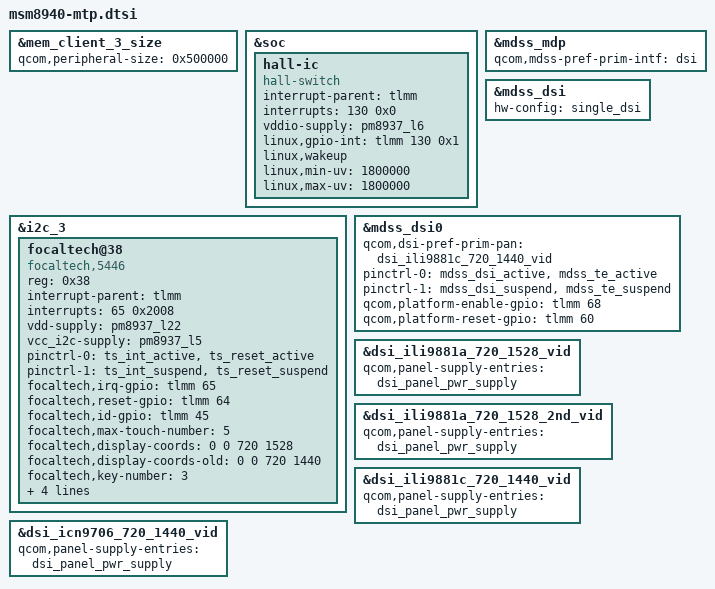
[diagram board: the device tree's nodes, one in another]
/*
 * Copyright (c) 2016, The Linux Foundation. All rights reserved.
 *
 * This program is free software; you can redistribute it and/or modify
 * it under the terms of the GNU General Public License version 2 and
 * only version 2 as published by the Free Software Foundation.
 *
 * This program is distributed in the hope that it will be useful,
 * but WITHOUT ANY WARRANTY; without even the implied warranty of
 * MERCHANTABILITY or FITNESS FOR A PARTICULAR PURPOSE.  See the
 * GNU General Public License for more details.
 */

#include "msm8937-mtp.dtsi"
#include "msm8940-pinctrl.dtsi"

&mem_client_3_size {
	qcom,peripheral-size = <0x500000>;
};

&soc {
	hall-ic{
		compatible = "hall-switch";
		//pinctrl-names = "default";
		//pinctrl-0 = <&hall_sensor_int_default>;
		interrupt-parent = <&tlmm>;
		interrupts = <130 0x0>;
		vddio-supply = <&pm8937_l6>;
		linux,gpio-int = <&tlmm 130 0x1>;
		linux,wakeup;
		linux,min-uv = <1800000>;
		linux,max-uv = <1800000>;
	};
};

&i2c_3{
		focaltech@38 {
			compatible = "focaltech,5446";
			reg = <0x38>;
			interrupt-parent = <&tlmm>;
			interrupts = <65 0x2008>;
			vdd-supply = <&pm8937_l22>;
			vcc_i2c-supply = <&pm8937_l5>;
			/* pins used by touchscreen */
			pinctrl-names = "pmx_ts_active","pmx_ts_suspend";//,"pmx_ts_release";
			pinctrl-0 = <&ts_int_active &ts_reset_active>;
			pinctrl-1 = <&ts_int_suspend &ts_reset_suspend>;
			//pinctrl-2 = <&ts_release>;
			focaltech,irq-gpio = <&tlmm 65 0x0>;
			focaltech,reset-gpio = <&tlmm 64 0x0>;
			focaltech,id-gpio = <&tlmm 45 0x0>;	//Add by Luoxingxing for TP compatibility.
			focaltech,max-touch-number = <5>;
			focaltech,display-coords = <0 0 720 1528>;
			focaltech,display-coords-old = <0 0 720 1440>;
//			focaltech,have-key;
			focaltech,key-number = <3>;
			focaltech,keys = <139 102 158>;
			focaltech,key-y-coord = <2000>;
			focaltech,key-x-coords = <200 600 800>;
//			focaltech,multi-vendor-with-same-ic;
//			focaltech,tp_forceupgrade-deviceid = <0x54>;
			focaltech,fw-auto-update;
		};
};

#include "msm8937-mdss-panels.dtsi"

&mdss_mdp {
	qcom,mdss-pref-prim-intf = "dsi";
};

&mdss_dsi {
	hw-config = "single_dsi";
};

&mdss_dsi0 {
	qcom,dsi-pref-prim-pan = <&dsi_ili9881c_720_1440_vid>;
	pinctrl-names = "mdss_default", "mdss_sleep";
	pinctrl-0 = <&mdss_dsi_active &mdss_te_active>;
	pinctrl-1 = <&mdss_dsi_suspend &mdss_te_suspend>;

 //	qcom,irq-te-tinno-vio = <&tlmm 24 0>;
//	qcom,platform-te-gpio = <&tlmm 24 0>;
	qcom,platform-enable-gpio = <&tlmm 68 0>;
	qcom,platform-reset-gpio = <&tlmm 60 0>;
//	qcom,platform-bklight-en-gpio = <&tlmm 98 0>;
};

&dsi_ili9881a_720_1528_vid {
	qcom,panel-supply-entries = <&dsi_panel_pwr_supply>;

};

&dsi_ili9881a_720_1528_2nd_vid {
	qcom,panel-supply-entries = <&dsi_panel_pwr_supply>;

};

&dsi_ili9881c_720_1440_vid {
	qcom,panel-supply-entries = <&dsi_panel_pwr_supply>;

};

&dsi_icn9706_720_1440_vid {
	qcom,panel-supply-entries = <&dsi_panel_pwr_supply>;

};
